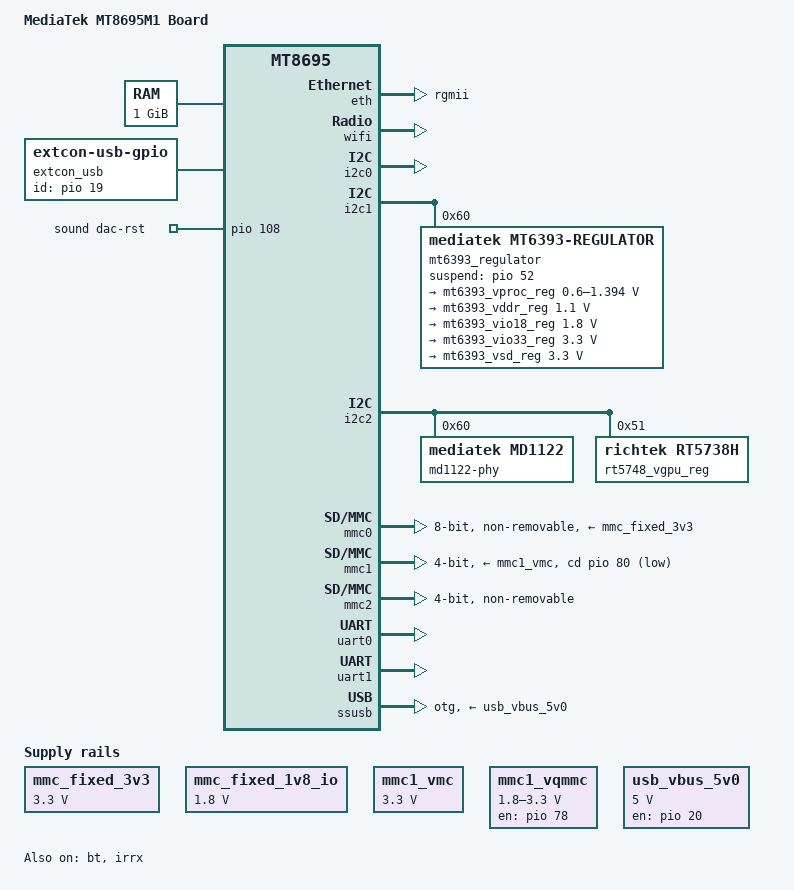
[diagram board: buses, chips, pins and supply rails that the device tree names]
/*
 * Copyright (c) 2017 MediaTek Inc.
 * Author: Joe Yang <joe.yang@mediatek.com>
 *
 * This program is free software; you can redistribute it and/or modify
 * it under the terms of the GNU General Public License version 2 as
 * published by the Free Software Foundation.
 *
 * This program is distributed in the hope that it will be useful,
 * but WITHOUT ANY WARRANTY; without even the implied warranty of
 * MERCHANTABILITY or FITNESS FOR A PARTICULAR PURPOSE.  See the
 * GNU General Public License for more details.
 */

/dts-v1/;
#include "mt8695.dtsi"

/ {
	model = "MediaTek MT8695M1 Board";
	compatible = "mediatek,mt8695m1", "mediatek,mt8695";

	memory@40000000 {
		device_type = "memory";
		reg = <0 0x40000000 0 0x40000000>;
	};

	extcon_usb: extcon_iddig {
		compatible = "linux,extcon-usb-gpio";
		id-gpio = <&pio 19 GPIO_ACTIVE_HIGH>;
	};

	chosen {
		bootargs = "console=tty0 console=ttyS1,921600n1 \
earlycon=uart8250,mmio32,0x11003000 root=/dev/ram initrd=0x44000000,0x600000 \
loglevel=8 initcall_debug=1 androidboot.selinux=permissive \
androidboot.hardware=mt8695 androidboot.serialno=0123456789ABCDEF";
	};

	mmc_fixed_3v3: fixedregulator@0 {
		compatible = "regulator-fixed";
		regulator-name = "mmc_power";
		regulator-min-microvolt = <3300000>;
		regulator-max-microvolt = <3300000>;
		enable-active-high;
		regulator-always-on;
	};

	mmc_fixed_1v8_io: fixedregulator@1 {
		compatible = "regulator-fixed";
		regulator-name = "mmc_io";
		regulator-min-microvolt = <1800000>;
		regulator-max-microvolt = <1800000>;
		enable-active-high;
		regulator-always-on;
	};

	mmc1_vmc: gpio-regulator@0 {
		compatible = "regulator-gpio";
		regulator-name = "mmc1_vmc";
		regulator-min-microvolt = <3300000>;
		regulator-max-microvolt = <3300000>;
		gpios = <&pio 79 GPIO_ACTIVE_HIGH>;
		states = <0 0x0
			  3300000 0x1>;
		startup-delay-us = <5000>;
		regulator-always-on;
	};

	mmc1_vqmmc: gpio-regulator@1 {
		compatible = "regulator-gpio";
		regulator-name = "mmc1_vqmmc";
		regulator-min-microvolt = <1800000>;
		regulator-max-microvolt = <3300000>;
		enable-gpio = <&pio 78 GPIO_ACTIVE_HIGH>;
		gpios = <&pio 81 GPIO_ACTIVE_HIGH>;
		states = <1800000 0x1
			  3300000 0x0>;
		startup-delay-us = <5000>;
		enable-active-high;
		regulator-always-on;
	};

	usb_vbus_5v0: fixedregulator@2 {
		compatible = "regulator-fixed";
		regulator-name = "vbus";
		regulator-min-microvolt = <5000000>;
		regulator-max-microvolt = <5000000>;
		gpio = <&pio 20 GPIO_ACTIVE_HIGH>;
		enable-active-high;
		regulator-type = "voltage";
	};

	sound: sound {
		compatible = "mediatek,mt8695-audio-card";
		mediatek,platform = <&afe>;
		pinctrl-names = "audio_default_pins";
		pinctrl-0 = <&audio_default_pins>;
		dac-rst-gpio = <&pio 108 0>;
		status = "okay";
	};
};

&bt {
	pinctrl-names = "default";
	pinctrl-0 = <&bt_default>;
	status = "okay";
};

&cpu0 {
	proc-supply = <&mt6393_vproc_reg>;
};

&cpu1 {
	proc-supply = <&mt6393_vproc_reg>;
};

&cpu2 {
	proc-supply = <&mt6393_vproc_reg>;
};

&cpu3 {
	proc-supply = <&mt6393_vproc_reg>;
};

&eth {
	pinctrl-names = "default";
	pinctrl-0 = <&eth_pins>;
	mac-address = [00 00 00 00 00 00];
	phy-mode = "rgmii";
	status = "okay";
};

&wifi {
	pinctrl-names = "default";
	pinctrl-0 = <&wifi_default>;
	status = "okay";
};

&hdmitx {
	pinctrl-names = "default";
	pinctrl-0 = <&hdmi_default>;
};

&i2c0 {
	pinctrl-names = "default";
	pinctrl-0 = <&i2c0_pins>;
	status = "okay";
};

&i2c1 {
	pinctrl-names = "default";
	pinctrl-0 = <&i2c1_pins>;
	status = "okay";

	mt6393_regulator: mt6393regulator@0x60 {
		compatible = "mediatek,mt6393-regulator";
		reg = <0x60>;
		pmic,suspend_gpio = <&pio 52 0>; /* pmic_suspend gpio number */
		normal_mode = <0>;

		mt6393_vproc_reg: buck_vproc {
			regulator-name = "vproc";
			regulator-min-microvolt = < 600000>;
			regulator-max-microvolt = <1393750>;
			regulator-always-on;
			regulator-boot-on;
		};

		mt6393_vddr_reg: buck_vddr {
			regulator-name = "vddr";
			regulator-min-microvolt = <1100000>;
			regulator-max-microvolt = <1100000>;
			regulator-always-on;
			regulator-boot-on;
		};

		mt6393_vio18_reg: buck_vio18 {
			regulator-name = "vio18";
			regulator-min-microvolt = <1800000>;
			regulator-max-microvolt = <1800000>;
			regulator-always-on;
			regulator-boot-on;
		};

		mt6393_vio33_reg: buck_vio33 {
			regulator-name = "vio33";
			regulator-min-microvolt = <3300000>;
			regulator-max-microvolt = <3300000>;
			regulator-always-on;
			regulator-boot-on;
		};

		mt6393_vsd_reg: ldo_sd {
			regulator-name = "sd";
			regulator-min-microvolt = <3300000>;
			regulator-max-microvolt = <3300000>;
			regulator-always-on;
			regulator-boot-on;
		};
	};
};

&i2c2 {
	pinctrl-names = "default";
	pinctrl-0 = <&i2c2_pins>;
	status = "okay";
	md1122-phy@60 {
		compatible = "mediatek,md1122";
		reg = <0x60>;
	};

	rt5748_vgpu_reg: rt5738_buck@51 {
		compatible = "richtek,rt5738h";
		reg = <0x51>;
		regulator-name = "rt5738-vgpu";
		regulator-min-microvolt = <300000>;
		regulator-max-microvolt = <1300000>;
		regulator-boot-on;
		regulator-enable-ramp-delay = <100>;
		ramp_up = <1>; /* 1 : 12mV/us */
		ramp_down = <3>; /* 3 : 3mV/us */
	};

	rt5748_vsram_reg: rt5738_buck@55 {
		compatible = "richtek,rt5738l";
		status = "disabled";
		reg = <0x55>;
		regulator-name = "rt5738-vsram";
		regulator-min-microvolt = <300000>;
		regulator-max-microvolt = <1300000>;
		regulator-always-on;
		regulator-boot-on;
		ramp_up = <1>; /* 1 : 12mV/us */
		ramp_down = <3>; /* 3 : 3mV/us */
	};
};

&irrx {
	pinctrl-names = "default";
	pinctrl-0 = <&irrx_pins_ir_input>;
	status = "okay";
};

&mmc0 {
	pinctrl-names = "default", "state_uhs";
	pinctrl-0 = <&mmc0_pins_default>;
	pinctrl-1 = <&mmc0_pins_uhs>;
	status = "okay";
	bus-width = <8>;
	max-frequency = <200000000>;
	cap-mmc-highspeed;
	mmc-hs200-1_8v;
	mmc-hs400-1_8v;
	cap-mmc-hw-reset;
	hs400-ds-delay = <0x14019>;
	r_smpl = <0>;
	vmmc-supply = <&mmc_fixed_3v3>;
	vqmmc-supply = <&mmc_fixed_1v8_io>;
	assigned-clocks = <&topckgen CLK_TOP_MSDC50_0_SEL>;
	assigned-clock-parents = <&topckgen CLK_TOP_MSDCPLL>;
	non-removable;
};

&mmc1 {
	pinctrl-names = "default", "state_uhs";
	pinctrl-0 = <&mmc1_pins_default>;
	pinctrl-1 = <&mmc1_pins_uhs>;
	status = "okay";
	bus-width = <4>;
	max-frequency = <200000000>;
	cap-sd-highspeed;
	sd-uhs-sdr50;
	sd-uhs-sdr104;
	cd-gpios = <&pio 80 GPIO_ACTIVE_LOW>;
	vmmc-supply = <&mmc1_vmc>;
	vqmmc-supply = <&mmc1_vqmmc>;
	assigned-clocks = <&topckgen CLK_TOP_MSDC30_1_SEL>;
	assigned-clock-parents = <&topckgen CLK_TOP_MSDCPLL_D2>;
};

&mmc2 {
	pinctrl-names = "default", "state_uhs", "state_dat1", "state_eint";
	pinctrl-0 = <&mmc2_pins_default>;
	pinctrl-1 = <&mmc2_pins_uhs>;
	pinctrl-2 = <&mmc2_pins_dat1>;
	pinctrl-3 = <&mmc2_dat1_eint>;
	eint-gpios = <&pio 32 0>;
	status = "okay";
	bus-width = <4>;
	max-frequency = <200000000>;
	cap-sd-highspeed;
	sd-uhs-sdr50;
	sd-uhs-sdr104;
	keep-power-in-suspend;
	enable-sdio-wakeup;
	cap-sdio-irq;
	non-removable;
	assigned-clocks = <&topckgen CLK_TOP_MSDC30_2_SEL>;
	assigned-clock-parents = <&topckgen CLK_TOP_MSDCPLL_D2>;
};

&uart0 {
	status = "okay";
};

&uart1 {
	pinctrl-names = "default";
	pinctrl-0 = <&uart1_pin>;
	status = "okay";
};

&pio {
	bt_default: bt {
		pins_cmd_dat {
			pinmux = <MT8695_PIN_27_GPIO27__FUNC_GPIO27>;
			input-enable;
		};
	};

	audio_default_pins: aud_pins {
		aud_pinmux {
			pinmux = <MT8695_PIN_100_I2SO0_BCK__FUNC_I2SO0_BCK>,
				 <MT8695_PIN_101_I2SO0_LRCK__FUNC_I2SO0_WS>,
				 <MT8695_PIN_102_I2SO0_MCLK__FUNC_I2SO0_MCK>,
				 <MT8695_PIN_103_I2SO0_DATA0__FUNC_I2SO0_DO>,
				 <MT8695_PIN_104_I2SO0_DATA1__FUNC_I2SO1_DO>,
				 <MT8695_PIN_105_I2SO1_MCLK__FUNC_I2SO2_DO>,
				 <MT8695_PIN_106_I2SO1_DATA__FUNC_I2SO3_DO>,
				 <MT8695_PIN_82_SPDIF__FUNC_SPDIF_OUT>;
		};
	};

	eth_pins: eth_default_pins {
		tx_pins {
			pinmux = <MT8695_PIN_120_GBE_TXD3__FUNC_GBE_TXD3>,
				 <MT8695_PIN_121_GBE_TXD2__FUNC_GBE_TXD2>,
				 <MT8695_PIN_122_GBE_TXD1__FUNC_GBE_TXD1>,
				 <MT8695_PIN_123_GBE_TXD0__FUNC_GBE_TXD0>,
				 <MT8695_PIN_124_GBE_TXC__FUNC_GBE_TXC>,
				 <MT8695_PIN_125_GBE_TXEN__FUNC_GBE_TXEN>;
		};
		rx_pins {
			pinmux = <MT8695_PIN_126_GBE_RXD3__FUNC_GBE_RXD3>,
				 <MT8695_PIN_127_GBE_RXD2__FUNC_GBE_RXD2>,
				 <MT8695_PIN_128_GBE_RXD1__FUNC_GBE_RXD1>,
				 <MT8695_PIN_129_GBE_RXD0__FUNC_GBE_RXD0>,
				 <MT8695_PIN_130_GBE_RXDV__FUNC_GBE_RXDV>,
				 <MT8695_PIN_132_GBE_RXC__FUNC_GBE_RXC>;
		};
		mdio_pins {
			pinmux = <MT8695_PIN_133_GBE_MDC__FUNC_GBE_MDC>,
				 <MT8695_PIN_134_GBE_MDIO__FUNC_GBE_MDIO>;
		};
		phy_rstb {
			pinmux = <MT8695_PIN_135_GBE_TXER__FUNC_GPIO135>;
			output-high;
		};
		gbe_intr {
			pinmux = <MT8695_PIN_136_GBE_INTR__FUNC_GBE_INTR>;
		};
		gbe_vio33_en {
			pinmux = <MT8695_PIN_137_GBE_COL__FUNC_GPIO137>;
			output-high;
		};
	};

	wifi_default: wifi {
		pins_cmd_dat {
			pinmux = <MT8695_PIN_26_GPIO26__FUNC_GPIO26>;
			input-enable;
		};
	};

	hdmi_default: hdmi {
		hdmi_cec {
			pinmux = <MT8695_PIN_72_HDMITX20_CEC__FUNC_HDMITX20_CEC>;
		};
		hdmi_pins {
			pinmux = <MT8695_PIN_74_HDMITX20_HDMISCK__FUNC_SCL_HDMI>,
				 <MT8695_PIN_75_HDMITX20_HDMISD__FUNC_SDA_HDMI>;
				 drive-strength = <MTK_DRIVE_10mA>;
				 bias-pull-up = <MTK_PUPD_SET_R1R0_01>;
		};
		hdmi_hotplug {
			pinmux = <MT8695_PIN_73_HDMITX20_HTPLG__FUNC_HDMITX20_HTPLG>;
			bias-pull-down;
		};
	};

	i2c0_pins: i2c0 {
		pins_bus {
			pinmux = <MT8695_PIN_117_SDA_EPM__FUNC_SDA_EPM>,
				 <MT8695_PIN_118_SCL_EPM__FUNC_SCL_EPM>;
			bias-disable;
		};
	};

	i2c1_pins: i2c1 {
		pins_bus {
			pinmux = <MT8695_PIN_56_SDA1__FUNC_SDA1>,
				 <MT8695_PIN_57_SCL1__FUNC_SCL1>;
			bias-disable;
		};
	};

	i2c2_pins: i2c2 {
		pins_bus {
			pinmux = <MT8695_PIN_76_SDA2__FUNC_SDA2>,
				 <MT8695_PIN_77_SCL2__FUNC_SCL2>;
			bias-disable;
		};
	};

	irrx_pins_ir_input: irrx_pin_ir {
		pins_cmd_dat {
			pinmux = <MT8695_PIN_51_IR__FUNC_IR_IN>;
			bias-disable;
		};
	};

	mmc0_pins_default: mmc0default {
		pins_cmd_dat {
			pinmux = <MT8695_PIN_44_EMMC_DAT0__FUNC_MSDC0_DAT0>,
				 <MT8695_PIN_43_EMMC_DAT1__FUNC_MSDC0_DAT1>,
				 <MT8695_PIN_42_EMMC_DAT2__FUNC_MSDC0_DAT2>,
				 <MT8695_PIN_41_EMMC_DAT3__FUNC_MSDC0_DAT3>,
				 <MT8695_PIN_40_EMMC_DAT4__FUNC_MSDC0_DAT4>,
				 <MT8695_PIN_39_EMMC_DAT5__FUNC_MSDC0_DAT5>,
				 <MT8695_PIN_38_EMMC_DAT6__FUNC_MSDC0_DAT6>,
				 <MT8695_PIN_37_EMMC_DAT7__FUNC_MSDC0_DAT7>,
				 <MT8695_PIN_45_EMMC_CMD__FUNC_MSDC0_CMD>;
			input-enable;
			drive-strength = <MTK_DRIVE_6mA>;
			bias-pull-up = <MTK_PUPD_SET_R1R0_01>;
		};

		pins_clk {
			pinmux = <MT8695_PIN_36_EMMC_CLK__FUNC_MSDC0_CLK>;
			drive-strength = <MTK_DRIVE_6mA>;
			bias-pull-down = <MTK_PUPD_SET_R1R0_10>;
		};

		pins_rst {
			pinmux = <MT8695_PIN_46_EMMC_RSTB__FUNC_MSDC0_RSTB>;
			bias-pull-up;
		};
	};

	mmc0_pins_uhs: mmc0@0{
		pins_cmd_dat {
			pinmux = <MT8695_PIN_44_EMMC_DAT0__FUNC_MSDC0_DAT0>,
				 <MT8695_PIN_43_EMMC_DAT1__FUNC_MSDC0_DAT1>,
				 <MT8695_PIN_42_EMMC_DAT2__FUNC_MSDC0_DAT2>,
				 <MT8695_PIN_41_EMMC_DAT3__FUNC_MSDC0_DAT3>,
				 <MT8695_PIN_40_EMMC_DAT4__FUNC_MSDC0_DAT4>,
				 <MT8695_PIN_39_EMMC_DAT5__FUNC_MSDC0_DAT5>,
				 <MT8695_PIN_38_EMMC_DAT6__FUNC_MSDC0_DAT6>,
				 <MT8695_PIN_37_EMMC_DAT7__FUNC_MSDC0_DAT7>,
				 <MT8695_PIN_45_EMMC_CMD__FUNC_MSDC0_CMD>;
			input-enable;
			drive-strength = <MTK_DRIVE_6mA>;
			bias-pull-up = <MTK_PUPD_SET_R1R0_01>;
		};

		pins_clk {
			pinmux = <MT8695_PIN_36_EMMC_CLK__FUNC_MSDC0_CLK>;
			drive-strength = <MTK_DRIVE_6mA>;
			bias-pull-down = <MTK_PUPD_SET_R1R0_10>;
		};

		pins_ds {
			pinmux = <MT8695_PIN_35_EMMC_DSL__FUNC_MSDC0_DSL>;
			drive-strength = <MTK_DRIVE_6mA>;
			bias-pull-down = <MTK_PUPD_SET_R1R0_10>;
		};

		pins_rst {
			pinmux = <MT8695_PIN_46_EMMC_RSTB__FUNC_MSDC0_RSTB>;
			bias-pull-up;
		};

	};

	mmc1_pins_default: mmc1default {
		pins_cmd_dat {
			pinmux = <MT8695_PIN_70_MSDC1_DATA0__FUNC_MSDC1_DAT0>,
				 <MT8695_PIN_68_MSDC1_DATA1__FUNC_MSDC1_DAT1>,
				 <MT8695_PIN_69_MSDC1_DATA2__FUNC_MSDC1_DAT2>,
				 <MT8695_PIN_67_MSDC1_DATA3__FUNC_MSDC1_DAT3>,
				 <MT8695_PIN_71_MSDC1_CMD__FUNC_MSDC1_CMD>;
			input-enable;
			drive-strength = <MTK_DRIVE_6mA>;
			bias-pull-up = <MTK_PUPD_SET_R1R0_01>;
		};

		pins_clk {
			pinmux = <MT8695_PIN_66_MSDC1_CLK__FUNC_MSDC1_CLK>;
			drive-strength = <MTK_DRIVE_6mA>;
			bias-pull-down = <MTK_PUPD_SET_R1R0_10>;
		};

		pins_insert {
			pinmux = <MT8695_PIN_80_GPIO80__FUNC_GPIO80>;
			input-enable;
			bias-pull-up;
		};
	};

	mmc1_pins_uhs: mmc1@0{
		pins_cmd_dat {
			pinmux = <MT8695_PIN_70_MSDC1_DATA0__FUNC_MSDC1_DAT0>,
				 <MT8695_PIN_68_MSDC1_DATA1__FUNC_MSDC1_DAT1>,
				 <MT8695_PIN_69_MSDC1_DATA2__FUNC_MSDC1_DAT2>,
				 <MT8695_PIN_67_MSDC1_DATA3__FUNC_MSDC1_DAT3>,
				 <MT8695_PIN_71_MSDC1_CMD__FUNC_MSDC1_CMD>;
			input-enable;
			drive-strength = <MTK_DRIVE_6mA>;
			bias-pull-up = <MTK_PUPD_SET_R1R0_01>;
		};

		pins_clk {
			pinmux = <MT8695_PIN_66_MSDC1_CLK__FUNC_MSDC1_CLK>;
			drive-strength = <MTK_DRIVE_6mA>;
			bias-pull-down = <MTK_PUPD_SET_R1R0_10>;
		};
	};

	mmc2_pins_default: mmc2default {
		pins_cmd_dat {
			pinmux = <MT8695_PIN_33_MSDC2_DATA0__FUNC_MSDC2_DAT0>,
			       <MT8695_PIN_32_MSDC2_DATA1__FUNC_MSDC2_DAT1>,
			       <MT8695_PIN_31_MSDC2_DATA2__FUNC_MSDC2_DAT2>,
			       <MT8695_PIN_30_MSDC2_DATA3__FUNC_MSDC2_DAT3>,
			       <MT8695_PIN_34_MSDC2_CMD__FUNC_MSDC2_CMD>;
			input-enable;
			drive-strength = <MTK_DRIVE_6mA>;
			bias-pull-up = <MTK_PUPD_SET_R1R0_01>;
		};

		pins_clk {
			pinmux = <MT8695_PIN_28_MSDC2_CLK__FUNC_MSDC2_CLK>;
			drive-strength = <MTK_DRIVE_6mA>;
			bias-pull-down = <MTK_PUPD_SET_R1R0_10>;
		};

		pins_pmu_en {
			pinmux = <MT8695_PIN_25_GPIO25__FUNC_GPIO25>;
			bias-pull-up;
		};
	};

	mmc2_pins_uhs: mmc2@0 {
		pins_cmd_dat {
			pinmux = <MT8695_PIN_33_MSDC2_DATA0__FUNC_MSDC2_DAT0>,
			       <MT8695_PIN_32_MSDC2_DATA1__FUNC_MSDC2_DAT1>,
			       <MT8695_PIN_31_MSDC2_DATA2__FUNC_MSDC2_DAT2>,
			       <MT8695_PIN_30_MSDC2_DATA3__FUNC_MSDC2_DAT3>,
			       <MT8695_PIN_34_MSDC2_CMD__FUNC_MSDC2_CMD>;
			input-enable;
			drive-strength = <MTK_DRIVE_6mA>;
			bias-pull-up = <MTK_PUPD_SET_R1R0_10>;
		};

		pins_clk {
			pinmux = <MT8695_PIN_28_MSDC2_CLK__FUNC_MSDC2_CLK>;
			drive-strength = <MTK_DRIVE_6mA>;
			bias-pull-down = <MTK_PUPD_SET_R1R0_10>;
		};

		pins_pmu_en {
			pinmux = <MT8695_PIN_25_GPIO25__FUNC_GPIO25>;
			bias-pull-up;
		};
	};

	mmc2_pins_dat1: mmc2_dat1 {
		pins_dat1 {
			pinmux = <MT8695_PIN_32_MSDC2_DATA1__FUNC_MSDC2_DAT1>;
			input-enable;
			drive-strength = <MTK_DRIVE_6mA>;
			bias-pull-up = <MTK_PUPD_SET_R1R0_10>;
		};
	};

	mmc2_dat1_eint: dat1_eint {
		pins_dat1_eint {
			pinmux = <MT8695_PIN_32_MSDC2_DATA1__FUNC_GPIO32>;
			input-enable;
			bias-pull-up = <MTK_PUPD_SET_R1R0_10>;
		};
	};

	uart1_pin: uart1default {
		pins_rx {
			pinmux = <MT8695_PIN_58_URXD1__FUNC_URXD1>;
			input-enable;
			bias-pull-up;
		};
		pins_tx {
			pinmux = <MT8695_PIN_59_UTXD1__FUNC_UTXD1>;
		};
	};

/* USB GPIO start */
	usb_id_pins_float: usb_iddig_pull_up {
		pins_iddig {
			pinmux = <MT8695_PIN_19_USB_ID__FUNC_IDDIG_A>;
			bias-pull-up;
		};
	};

	usb_id_pins_ground: usb_iddig_pull_down {
		pins_iddig {
			pinmux = <MT8695_PIN_19_USB_ID__FUNC_IDDIG_A>;
			bias-pull-down;
		};
	};
};

&ssusb {
	vbus-supply = <&usb_vbus_5v0>;
	extcon = <&extcon_usb>;
	dr_mode = "otg"; /* 1: host, 2: peripheral, 3: otg (dual-mode) */
	/* mediatek,enable-wakeup; */
	/* enable-manual-drd; */
	pinctrl-names = "default", "id_float", "id_ground";
	pinctrl-0 = <&usb_id_pins_float>;
	pinctrl-1 = <&usb_id_pins_float>;
	pinctrl-2 = <&usb_id_pins_ground>;
	status = "okay";
};

&mfg {
	reg-vgpu-supply = <&rt5748_vgpu_reg>;
};

&svs {
	vproc-supply = <&mt6393_vproc_reg>;
};
